# STM32G0B1 register map
File version: 1.5
CPU: CM0 r0p1, little endian, MPU, no FPU, 4 interrupt priority bits
Registers are 32-bit, read-write, reset 0x0 unless marked. A register's access mark holds for its fields unless they carry their own. Offsets are from the block's base; [hi:lo] are bit positions; {n}, {i} and the like mark numbered series; 'fields as' and 'values as' point back to an identical list.

## SPI1 — Serial peripheral interface
Base 0x40013000
Same registers: SPI2 0x40003800, SPI3 0x40003C00
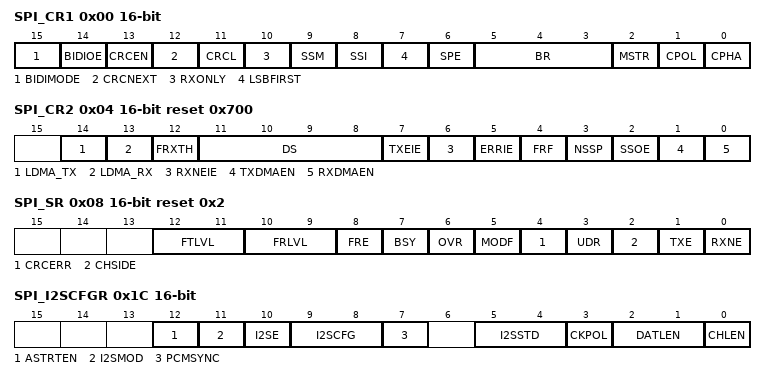
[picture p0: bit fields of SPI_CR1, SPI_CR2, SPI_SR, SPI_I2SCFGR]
0x00 SPI_CR1 16-bit — SPI control register 1
  [15] BIDIMODE — Bidirectional data mode enable. This bit enables half-duplex communication using common single bidirectional data line. Keep RXONLY bit clear when bidirectional mode is active. Note: This bit is not used in I2S mode.
    0=2-line unidirectional data mode selected; 1=1-line bidirectional data mode selected
  [14] BIDIOE — Output enable in bidirectional mode This bit combined with the BIDIMODE bit selects the direction of transfer in bidirectional mode. Note: In master mode, the MOSI pin is used and in slave mode, the MISO pin is used. This bit is not used in I2S mode.
    0=Output disabled (receive-only mode); 1=Output enabled (transmit-only mode)
  [13] CRCEN — Hardware CRC calculation enable Note: This bit should be written only when SPI is disabled (SPE = '0') for correct operation. This bit is not used in I2S mode.
    0=CRC calculation disabled; 1=CRC calculation enabled
  [12] CRCNEXT — Transmit CRC next Note: This bit has to be written as soon as the last data is written in the SPI_DR register. This bit is not used in I2S mode.
    0=Next transmit value is from Tx buffer; 1=Next transmit value is from Tx CRC register
  [11] CRCL — CRC length This bit is set and cleared by software to select the CRC length. Note: This bit should be written only when SPI is disabled (SPE = '0') for correct operation. This bit is not used in I2S mode.
    0=8-bit CRC length; 1=16-bit CRC length
  [10] RXONLY — Receive only mode enabled. This bit enables simplex communication using a single unidirectional line to receive data exclusively. Keep BIDIMODE bit clear when receive only mode is active.This bit is also useful in a multislave system in which this particular slave is not accessed, the output from the accessed slave is not corrupted. Note: This bit is not used in I2S mode.
    0=Full-duplex (Transmit and receive); 1=Output disabled (Receive-only mode)
  [9] SSM — Software slave management When the SSM bit is set, the NSS pin input is replaced with the value from the SSI bit. Note: This bit is not used in I2S mode and SPI TI mode.
    0=Software slave management disabled; 1=Software slave management enabled
  [8] SSI — Internal slave select This bit has an effect only when the SSM bit is set. The value of this bit is forced onto the NSS pin and the I/O value of the NSS pin is ignored. Note: This bit is not used in I2S mode and SPI TI mode.
  [7] LSBFIRST — Frame format Note: 1. This bit should not be changed when communication is ongoing. 2. This bit is not used in I2S mode and SPI TI mode.
    0=data is transmitted / received with the MSB first; 1=data is transmitted / received with the LSB first
  [6] SPE — SPI enable Note: When disabling the SPI, follow the procedure described in SPI on page 1021. This bit is not used in I2S mode.
    0=Peripheral disabled; 1=Peripheral enabled
  [5:3] BR — Baud rate control Note: These bits should not be changed when communication is ongoing. These bits are not used in I2S mode.
    0=fPCLK/2; 1=fPCLK/4; 2=fPCLK/8; 3=fPCLK/16; 4=fPCLK/32; 5=fPCLK/64; 6=fPCLK/128; 7=fPCLK/256
  [2] MSTR — Master selection Note: This bit should not be changed when communication is ongoing. This bit is not used in I2S mode.
    0=Slave configuration; 1=Master configuration
  [1] CPOL — Clock polarity Note: This bit should not be changed when communication is ongoing. This bit is not used in I2S mode and SPI TI mode except the case when CRC is applied at TI mode.
    0=CK to 0 when idle; 1=CK to 1 when idle
  [0] CPHA — Clock phase Note: This bit should not be changed when communication is ongoing. This bit is not used in I2S mode and SPI TI mode except the case when CRC is applied at TI mode.
    0=The first clock transition is the first data capture edge; 1=The second clock transition is the first data capture edge
0x04 SPI_CR2 16-bit reset 0x700 — SPI control register 2
  [14] LDMA_TX — Last DMA transfer for transmission This bit is used in data packing mode, to define if the total number of data to transmit by DMA is odd or even. It has significance only if the TXDMAEN bit in the SPI_CR2 register is set and if packing mode is used (data length =< 8-bit and write access to SPI_DR is 16-bit wide). It has to be written when the SPI is disabled (SPE = 0 in the SPI_CR1 register). Note: Refer to if the CRCEN bit is set. This bit is not used in I2S mode.
    0=Number of data to transfer is even; 1=Number of data to transfer is odd
  [13] LDMA_RX — Last DMA transfer for reception This bit is used in data packing mode, to define if the total number of data to receive by DMA is odd or even. It has significance only if the RXDMAEN bit in the SPI_CR2 register is set and if packing mode is used (data length =< 8-bit and write access to SPI_DR is 16-bit wide). It has to be written when the SPI is disabled (SPE = 0 in the SPI_CR1 register). Note: Refer to if the CRCEN bit is set. This bit is not used in I2S mode.
    values as LDMA_TX
  [12] FRXTH — FIFO reception threshold This bit is used to set the threshold of the RXFIFO that triggers an RXNE event Note: This bit is not used in I2S mode.
    0=RXNE event is generated if the FIFO level is greater than or equal to 1/2 (16-bit); 1=RXNE event is generated if the FIFO level is greater than or equal to 1/4 (8-bit)
  [11:8] DS — Data size These bits configure the data length for SPI transfers. If software attempts to write one of the "Not used" values, they are forced to the value "0111" (8-bit) Note: These bits are not used in I2S mode.
    {v}={v+1}-bit (v=3..15)
  [7] TXEIE — Tx buffer empty interrupt enable
    0=TXE interrupt masked; 1=TXE interrupt not masked. Used to generate an interrupt request when the TXE flag is set.
  [6] RXNEIE — RX buffer not empty interrupt enable
    0=RXNE interrupt masked; 1=RXNE interrupt not masked. Used to generate an interrupt request when the RXNE flag is set.
  [5] ERRIE — Error interrupt enable This bit controls the generation of an interrupt when an error condition occurs (CRCERR, OVR, MODF in SPI mode, FRE at TI mode and UDR, OVR, and FRE in I2S mode).
    0=Error interrupt is masked; 1=Error interrupt is enabled
  [4] FRF — Frame format 1 SPI TI mode Note: This bit must be written only when the SPI is disabled (SPE=0). This bit is not used in I2S mode.
    0=SPI Motorola mode
  [3] NSSP — NSS pulse management This bit is used in master mode only. it allows the SPI to generate an NSS pulse between two consecutive data when doing continuous transfers. In the case of a single data transfer, it forces the NSS pin high level after the transfer. It has no meaning if CPHA = '1', or FRF = '1'. Note: 1. This bit must be written only when the SPI is disabled (SPE=0). 2. This bit is not used in I2S mode and SPI TI mode.
    0=No NSS pulse; 1=NSS pulse generated
  [2] SSOE — SS output enable Note: This bit is not used in I2S mode and SPI TI mode.
    0=SS output is disabled in master mode and the SPI interface can work in multimaster configuration; 1=SS output is enabled in master mode and when the SPI interface is enabled. The SPI interface cannot work in a multimaster environment.
  [1] TXDMAEN — Tx buffer DMA enable When this bit is set, a DMA request is generated whenever the TXE flag is set.
    0=Tx buffer DMA disabled; 1=Tx buffer DMA enabled
  [0] RXDMAEN — Rx buffer DMA enable When this bit is set, a DMA request is generated whenever the RXNE flag is set.
    0=Rx buffer DMA disabled; 1=Rx buffer DMA enabled
0x08 SPI_SR 16-bit access per field reset 0x2 — SPI status register
  [12:11] FTLVL ro — FIFO transmission level These bits are set and cleared by hardware. Note: This bit is not used in I2S mode.
    0=FIFO empty; 1=1/4 FIFO; 2=1/2 FIFO; 3=FIFO full (considered as FULL when the FIFO threshold is greater than 1/2)
  [10:9] FRLVL ro — FIFO reception level These bits are set and cleared by hardware. Note: These bits are not used in I2S mode and in SPI receive-only mode while CRC calculation is enabled.
    0=FIFO empty; 1=1/4 FIFO; 2=1/2 FIFO; 3=FIFO full
  [8] FRE ro — Frame format error This flag is used for SPI in TI slave mode and I2S slave mode. Refer to error flags and . This flag is set by hardware and reset when SPI_SR is read by software.
    0=No frame format error; 1=A frame format error occurred
  [7] BSY ro — Busy flag This flag is set and cleared by hardware. Note: The BSY flag must be used with caution: refer to and .
    0=SPI (or I2S) not busy; 1=SPI (or I2S) is busy in communication or Tx buffer is not empty
  [6] OVR ro — Overrun flag This flag is set by hardware and reset by a software sequence. Refer to page 1057 for the software sequence.
    0=No overrun occurred; 1=Overrun occurred
  [5] MODF ro — Mode fault This flag is set by hardware and reset by a software sequence. Refer to (MODF) on page 1031 for the software sequence. Note: This bit is not used in I2S mode.
    0=No mode fault occurred; 1=Mode fault occurred
  [4] CRCERR rw — CRC error flag Note: This flag is set by hardware and cleared by software writing 0. This bit is not used in I2S mode.
    0=CRC value received matches the SPI_RXCRCR value; 1=CRC value received does not match the SPI_RXCRCR value
  [3] UDR ro — Underrun flag This flag is set by hardware and reset by a software sequence. Refer to page 1057 for the software sequence. Note: This bit is not used in SPI mode.
    0=No underrun occurred; 1=Underrun occurred
  [2] CHSIDE ro — Channel side Note: This bit is not used in SPI mode. It has no significance in PCM mode.
    0=Channel Left has to be transmitted or has been received; 1=Channel Right has to be transmitted or has been received
  [1] TXE ro — Transmit buffer empty
    0=Tx buffer not empty; 1=Tx buffer empty
  [0] RXNE ro — Receive buffer not empty
    0=Rx buffer empty; 1=Rx buffer not empty
0x0C SPI_DR 16-bit — SPI data register
  [15:0] DR — Data register Data received or to be transmitted The data register serves as an interface between the Rx and Tx FIFOs. When the data register is read, RxFIFO is accessed while the write to data register accesses TxFIFO (See ). Note: Data is always right-aligned. Unused bits are ignored when writing to the register, and read as zero when the register is read. The Rx threshold setting must always correspond with the read access currently used.
0x10 SPI_CRCPR 16-bit reset 0x7 — SPI CRC polynomial register
  [15:0] CRCPOLY — CRC polynomial register This register contains the polynomial for the CRC calculation. The CRC polynomial (0x0007) is the reset value of this register. Another polynomial can be configured as required.
0x14 SPI_RXCRCR 16-bit ro — SPI Rx CRC register
  [15:0] RXCRC — Rx CRC register When CRC calculation is enabled, the RXCRC[15:0] bits contain the computed CRC value of the subsequently received bytes. This register is reset when the CRCEN bit in SPI_CR1 register is written to 1. The CRC is calculated serially using the polynomial programmed in the SPI_CRCPR register. Only the 8 LSB bits are considered when the CRC frame format is set to be 8-bit length (CRCL bit in the SPI_CR1 is cleared). CRC calculation is done based on any CRC8 standard. The entire 16-bits of this register are considered when a 16-bit CRC frame format is selected (CRCL bit in the SPI_CR1 register is set). CRC calculation is done based on any CRC16 standard. Note: A read to this register when the BSY Flag is set could return an incorrect value. These bits are not used in I2S mode.
0x18 SPI_TXCRCR 16-bit ro — SPI Tx CRC register
  [15:0] TXCRC — Tx CRC register When CRC calculation is enabled, the TXCRC[7:0] bits contain the computed CRC value of the subsequently transmitted bytes. This register is reset when the CRCEN bit of SPI_CR1 is written to 1. The CRC is calculated serially using the polynomial programmed in the SPI_CRCPR register. Only the 8 LSB bits are considered when the CRC frame format is set to be 8-bit length (CRCL bit in the SPI_CR1 is cleared). CRC calculation is done based on any CRC8 standard. The entire 16-bits of this register are considered when a 16-bit CRC frame format is selected (CRCL bit in the SPI_CR1 register is set). CRC calculation is done based on any CRC16 standard. Note: A read to this register when the BSY flag is set could return an incorrect value. These bits are not used in I2S mode.
0x1C SPI_I2SCFGR 16-bit — SPI_I2S configuration register
  [12] ASTRTEN — Asynchronous start enable. When the I2S is enabled in slave mode, the hardware starts the transfer when the I2S clock is received and an appropriate transition is detected on the WS signal. When the I2S is enabled in slave mode, the hardware starts the transfer when the I2S clock is received and the appropriate level is detected on the WS signal. Note: The appropriate transition is a falling edge on WS signal when I2S Philips Standard is used, or a rising edge for other standards. The appropriate level is a low level on WS signal when I2S Philips Standard is used, or a high level for other standards. Please refer to for additional information.
    0=The Asynchronous start is disabled; 1=The Asynchronous start is enabled
  [11] I2SMOD — I2S mode selection Note: This bit should be configured when the SPI is disabled.
    0=SPI mode is selected; 1=I2S mode is selected
  [10] I2SE — I2S enable Note: This bit is not used in SPI mode.
    0=I2S peripheral is disabled; 1=I2S peripheral is enabled
  [9:8] I2SCFG — I2S configuration mode Note: These bits should be configured when the I2S is disabled. They are not used in SPI mode.
    0=Slave - transmit; 1=Slave - receive; 2=Master - transmit; 3=Master - receive
  [7] PCMSYNC — PCM frame synchronization Note: This bit has a meaning only if I2SSTD = 11 (PCM standard is used). It is not used in SPI mode.
    0=Short frame synchronization; 1=Long frame synchronization
  [5:4] I2SSTD — I2S standard selection For more details on I2S standards, refer to Note: For correct operation, these bits should be configured when the I2S is disabled. They are not used in SPI mode.
    0=I2S Philips standard; 1=MSB justified standard (left justified); 2=LSB justified standard (right justified); 3=PCM standard
  [3] CKPOL — Inactive state clock polarity Note: For correct operation, this bit should be configured when the I2S is disabled. It is not used in SPI mode. The bit CKPOL does not affect the CK edge sensitivity used to receive or transmit the SD and WS signals.
    0=I2S clock inactive state is low level; 1=I2S clock inactive state is high level
  [2:1] DATLEN — Data length to be transferred Note: For correct operation, these bits should be configured when the I2S is disabled. They are not used in SPI mode.
    0=16-bit data length; 1=24-bit data length; 2=32-bit data length; 3=Not allowed
  [0] CHLEN — Channel length (number of bits per audio channel) The bit write operation has a meaning only if DATLEN = 00 otherwise the channel length is fixed to 32-bit by hardware whatever the value filled in. Note: For correct operation, this bit should be configured when the I2S is disabled. It is not used in SPI mode.
    0=16-bit wide; 1=32-bit wide
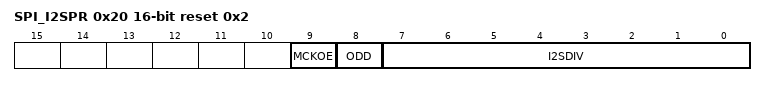
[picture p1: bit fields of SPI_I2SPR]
0x20 SPI_I2SPR 16-bit reset 0x2 — SPI_I2S prescaler register
  [9] MCKOE — Master clock output enable Note: This bit should be configured when the I2S is disabled. It is used only when the I2S is in master mode. It is not used in SPI mode.
    0=Master clock output is disabled; 1=Master clock output is enabled
  [8] ODD — Odd factor for the prescaler Refer to . Note: This bit should be configured when the I2S is disabled. It is used only when the I2S is in master mode. It is not used in SPI mode.
    0=Real divider value is = I2SDIV *2; 1=Real divider value is = (I2SDIV * 2) + 1
  [7:0] I2SDIV — I2S linear prescaler I2SDIV [7:0] = 0 or I2SDIV [7:0] = 1 are forbidden values. Refer to . Note: These bits should be configured when the I2S is disabled. They are used only when the I2S is in master mode. They are not used in SPI mode.
